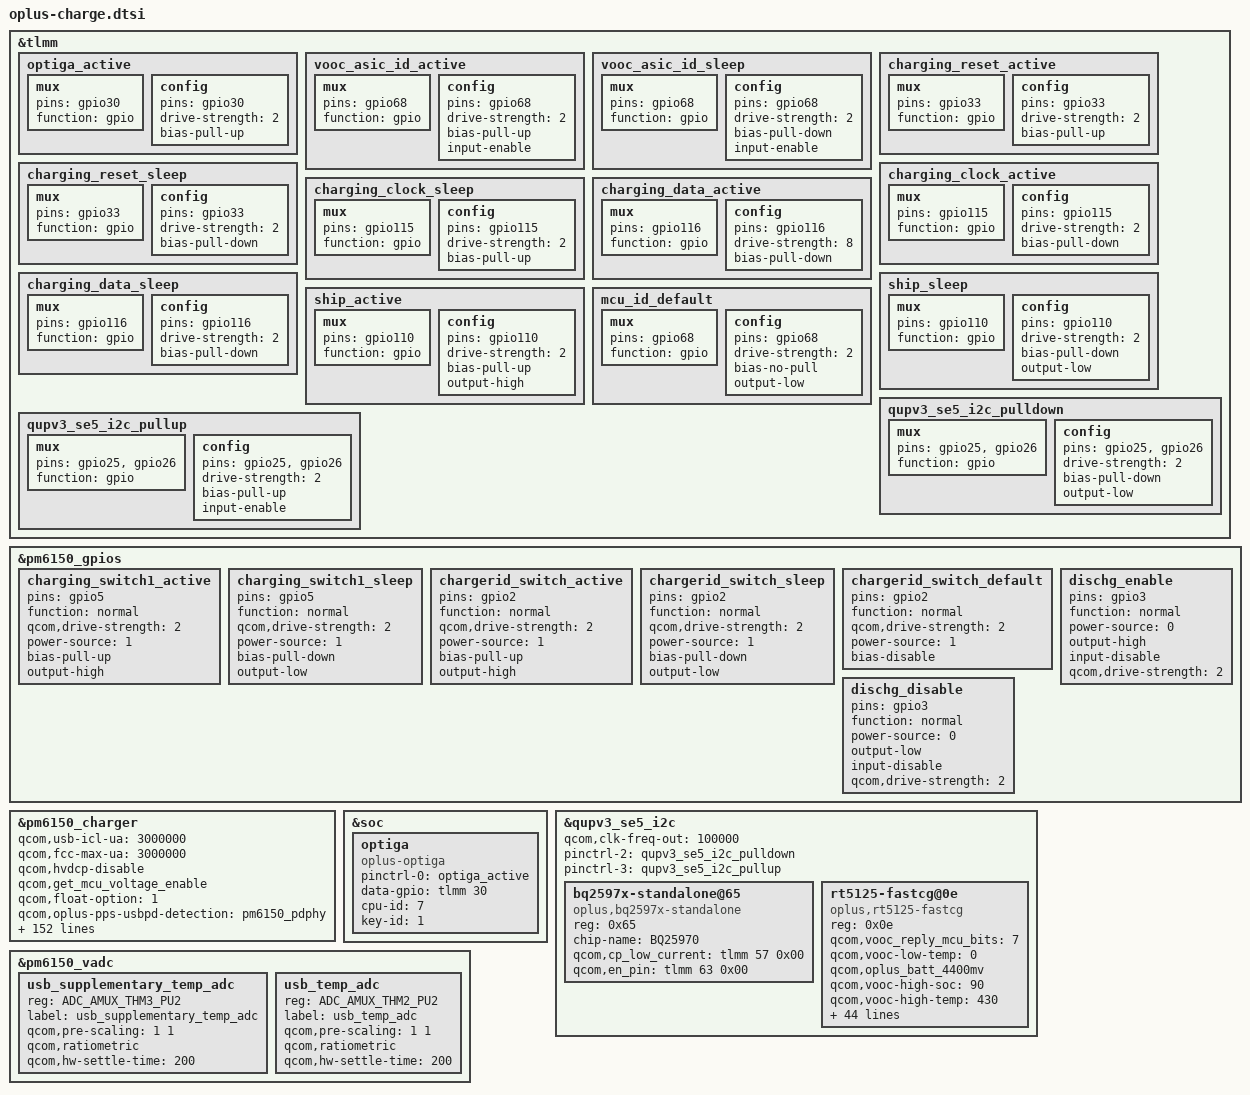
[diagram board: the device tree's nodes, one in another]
/**********************************************************************************
* Copyright (c)  2008-2019  Guangdong oplus Mobile Comm Corp., Ltd
*  
* Description: oplus Charge Module Device Tree
* 
* Version: 1.0
* Date: 2019-06-10
* Author: Gang.Yan
* 
* ------------------------------ Revision History: --------------------------------
* <version>           <date>                <author>                            <desc>
* Revision 1.0       2020-03-07            Gang.Yan             Created for new architecture
***********************************************************************************/

&tlmm {
	optiga_active: optiga_active {
				mux {
					pins = "gpio30";
					function = "gpio";
				};

				config {
					pins = "gpio30";
					drive-strength = <2>;
					bias-pull-up;
				};
	};

	vooc_asic_id_active: vooc_asic_id_active {
		mux {
			pins = "gpio68";
			function = "gpio";
		};

		config {
			pins = "gpio68";
			drive-strength = <2>;
			bias-pull-up;
			input-enable;
		};
	};

	vooc_asic_id_sleep: vooc_asic_id_sleep {
		mux {
			pins = "gpio68";
			function = "gpio";
		};

		config {
			pins = "gpio68";
			drive-strength = <2>;
			bias-pull-down;
			input-enable;
		};
	};

			charging_reset_active: charging_reset_active {
				mux {
					pins = "gpio33";
					function = "gpio";
				};

				config {
					pins = "gpio33";
					drive-strength = <2>;
					bias-pull-up;
				};
			};

			charging_reset_sleep: charging_reset_sleep {
				mux {
					pins = "gpio33";
					function = "gpio";
				};

				config {
					pins = "gpio33";
					drive-strength = <2>;
					bias-pull-down;
				};
			};

			charging_clock_active: charging_clock_active {
				mux {
					pins = "gpio115";
					function = "gpio";
				};

				config {
					pins = "gpio115";
					drive-strength = <2>;
					bias-pull-down;
				};
			};

			charging_clock_sleep: charging_clock_sleep {
				mux {
					pins = "gpio115";
					function = "gpio";
				};

				config {
					pins = "gpio115";
					drive-strength = <2>;
					bias-pull-up;
				};
			};

			charging_data_active: charging_data_active {
				mux {
					pins = "gpio116";
					function = "gpio";
				};

				config {
					pins = "gpio116";
					drive-strength = <8>;
					bias-pull-down;
				};
			};

			charging_data_sleep: charging_data_sleep {
				mux {
					pins = "gpio116";
					function = "gpio";
				};

				config {
					pins = "gpio116";
					drive-strength = <2>;
					bias-pull-down;
				};
			};


	ship_sleep: ship_sleep {
		mux {
			pins = "gpio110";
			function = "gpio";
		};

		config {
			pins = "gpio110";
			drive-strength = <2>;
			bias-pull-down;
			output-low;
		};
	};

	ship_active: ship_active {
		mux {
			pins = "gpio110";
			function = "gpio";
		};

		config {
			pins = "gpio110";
			drive-strength = <2>;
			bias-pull-up;
			output-high;
		};
	};

	
	mcu_id_default: mcu_id_default {
		mux {
					pins = "gpio68";
			function = "gpio";
		};

		config {
					pins = "gpio68";
			drive-strength = <2>;
			bias-no-pull;
			output-low;
		};
	};
			qupv3_se5_i2c_pulldown: qupv3_se5_i2c_pulldown {
				mux {
					pins = "gpio25", "gpio26";
					function = "gpio";
				};

				config {
					pins = "gpio25", "gpio26";
					drive-strength = <2>;
					bias-pull-down;
					output-low;
				};
			};

			qupv3_se5_i2c_pullup: qupv3_se5_i2c_pullup {
				mux {
					pins = "gpio25", "gpio26";
					function = "gpio";
				};

				config {
					pins = "gpio25", "gpio26";
					drive-strength = <2>;
					bias-pull-up;
					input-enable;
				};
			};
			//#endif
};

&pm6150_gpios {
	charging_switch1_active: charging_switch1_active {
		pins = "gpio5";
		function = "normal";
		qcom,drive-strength = <2>;
		power-source = <1>;
		bias-pull-up;
		output-high;
	};

	charging_switch1_sleep: charging_switch1_sleep {
		pins = "gpio5";
		function = "normal";
		qcom,drive-strength = <2>;
		power-source = <1>;
		bias-pull-down;
		output-low;
	};

	chargerid_switch_active: chargerid_switch_active {
		pins = "gpio2";
		function = "normal";
		qcom,drive-strength = <2>;
		power-source = <1>;
		bias-pull-up;
		output-high;
	};

	chargerid_switch_sleep: chargerid_switch_sleep {
		pins = "gpio2";
		function = "normal";
		qcom,drive-strength = <2>;
		power-source = <1>;
		bias-pull-down;
		output-low;
	};

	chargerid_switch_default: chargerid_switch_default {
		pins = "gpio2";
		function = "normal";
		qcom,drive-strength = <2>;
		power-source = <1>;
		bias-disable;
	};
	dischg_enable: dischg_enable {
		pins = "gpio3";
		function = "normal";
		power-source = <0>;
		output-high;
		input-disable;
		qcom,drive-strength = <2>;
	};

	dischg_disable: dischg_disable {
		pins = "gpio3";
		function = "normal";
		power-source = <0>;
		output-low;
		input-disable;
		qcom,drive-strength = <2>;
	};
};

&pm6150_charger {
			qcom,usb-icl-ua = <3000000>;
			qcom,fcc-max-ua = <3000000>;
			qcom,hvdcp-disable;
			qcom,get_mcu_voltage_enable;
			qcom,float-option = <1>;
			qcom,oplus-pps-usbpd-detection = <&pm6150_pdphy>;
			//for oplus chg framework:
			qcom,smart_charging_screenoff;
			qcom,input_current_charger_ma = <2000>;
			qcom,pd_input_current_charger_ma = <1500>;
			qcom,qc_input_current_charger_ma = <1500>;
			qcom,input_current_usb_ma = <500>;

			qcom,input_current_led_ma = <1200>;
			qcom,input_current_led_ma_high = <1200>;
			qcom,input_current_led_ma_warm = <1500>;
			qcom,input_current_led_ma_normal = <2000>;

			qcom,input_current_camera_ma = <1200>;
			qcom,input_current_cdp_ma = <1600>;
			//qcom,input_current_led_ma_overtemp = <900>;
			qcom,overtemp_bat_decidegc = <350>;
			qcom,iterm_disabled = <0>;
			sw_full_count = <25>;
			qcom,iterm_ma = <221>;
			qcom,recharge-mv = <100>;
			qcom,batt_capacity_mah = <4220>;/*typical capacity*/
			//qcom,batt_capacity_mah = <3920>; /*rated capacity*/

			qcom,removed_bat_decidegc = <190>;  /*<-19C*/

			qcom,cold_bat_decidegc = <20>;  /*-2C~0C*/
			qcom,temp_cold_vfloat_mv = <3980>;
			qcom,temp_cold_fastchg_current_ma = <314>;

			qcom,little_cold_bat_decidegc = <0>;	/*0C~5C*/
			qcom,temp_little_cold_vfloat_mv = <4435>;
			qcom,temp_little_cold_fastchg_current_ma_high = <2200>;
			qcom,temp_little_cold_fastchg_current_ma_low = <2200>;
			qcom,pd_temp_little_cold_fastchg_current_ma_high = <2594>;
			qcom,pd_temp_little_cold_fastchg_current_ma_low = <3300>;
			qcom,temp_little_cold_fastchg_current_ma = <1076>;
			qcom,qc_temp_little_cold_fastchg_current_ma_high = <2594>;
			qcom,qc_temp_little_cold_fastchg_current_ma_low = <3300>;
        
			qcom,cool_bat_decidegc = <50>;	/*5C~12C*/
			qcom,temp_cool_vfloat_mv = <4435>;
			qcom,temp_cool_fastchg_current_ma_high = <2200>;
			qcom,temp_cool_fastchg_current_ma_low = <2200>;
			qcom,qc_temp_cool_fastchg_current_ma_high = <3300>;	//2464
			qcom,qc_temp_cool_fastchg_current_ma_low = <3300>;	//1760
			qcom,pd_temp_cool_fastchg_current_ma_high = <3300>;	//2464
			qcom,pd_temp_cool_fastchg_current_ma_low = <3300>;	//1760

			qcom,little_cool_bat_decidegc = <120>;	/*12C~16C*/
			qcom,temp_little_cool_vfloat_mv = <4435>;
			qcom,temp_little_cool_fastchg_current_ma = <2200>;
			qcom,pd_temp_little_cool_fastchg_current_ma = <3300>;
			qcom,qc_temp_little_cool_fastchg_current_ma = <3300>;
	
			qcom,normal_bat_decidegc = <160>;	/*16C~44C*/
			qcom,temp_normal_fastchg_current_ma = <2200>;
			qcom,pd_temp_normal_fastchg_current_ma = <3300>;
			qcom,qc_temp_normal_fastchg_current_ma = <3300>;
			qcom,temp_normal_vfloat_mv = <4435>;

			qcom,warm_bat_decidegc = <450>;		/*44C~53C*/ /*8pin Bat Vooc project need add 3 degree C*/
			qcom,temp_warm_vfloat_mv = <4130>;
			qcom,temp_warm_fastchg_current_ma = <1152>;
			qcom,pd_temp_warm_fastchg_current_ma = <1152>;
			qcom,qc_temp_warm_fastchg_current_ma = <1152>;
			qcom,temp_warm_fastchg_current_ma_led_on = <500>;
	
			qcom,hot_bat_decidegc = <530>;

			qcom,non_standard_vfloat_mv = <3980>;
			qcom,non_standard_fastchg_current_ma = <550>;
	
			qcom,short_c_bat_cv_mv = <4330>;
			qcom,short_c_bat_vfloat_mv = <3800>;
			qcom,short_c_bat_fastchg_current_ma = <512>;

			qcom,cold_vfloat_sw_limit = <3930>;
			qcom,little_cold_vfloat_sw_limit = <4370>;
			qcom,cool_vfloat_sw_limit = <4370>;
			qcom,little_cool_vfloat_sw_limit = <4370>;
			qcom,normal_vfloat_sw_limit = <4435>;
			qcom,warm_vfloat_sw_limit = <4080>;
			qcom,non_standard_vfloat_sw_limit = <3930>;
			qcom,short_c_bat_vfloat_sw_limit = <3750>;

			qcom,max_chg_time_sec = <36000>;
			qcom,charger_hv_thr = <11000>;
			qcom,charger_recv_thr = <9700>;
			qcom,charger_lv_thr = <3400>;
			qcom,vbatt_full_thr = <4400>;
			qcom,vbatt_hv_thr = <4600>;
			qcom,vfloat_step_mv = <16>;
			qcom,non_standard_vfloat_over_sw_limit = <3980>;
			qcom,cold_vfloat_over_sw_limit = <3980>;
			qcom,little_cold_vfloat_over_sw_limit = <4440>;
			qcom,cool_vfloat_over_sw_limit = <4440>;
			qcom,little_cool_vfloat_over_sw_limit = <4440>;
			qcom,normal_vfloat_over_sw_limit = <4440>;
			qcom,warm_vfloat_over_sw_limit = <4130>;

			qcom,vbatt_power_off = <3300>;
			qcom,vbatt_soc_1 = <3410>;
			qcom,vooc_project = <3>;
			qcom,vbatt_num = <1>;
			qcom,ffc_support;

			qcom,normal_vterm_hw_inc = <18>;
			qcom,non_normal_vterm_hw_inc = <18>;

			qcom,ff1_normal_fastchg_ma = <1550>;
			qcom,ff1_warm_fastchg_ma = <1750>;	/* 35C ~ 40c */
			qcom,ff1_exit_step_ma = <100>;
			qcom,ff1_warm_exit_step_ma = <150>;
			qcom,ffc2_normal_fastchg_ma = <1550>;/*12C~35c*/
			qcom,ffc2_warm_fastchg_ma = <1750>;	/* 35C ~ 40c */
			qcom,ffc2_temp_warm_decidegc = <350>;
			qcom,ffc2_temp_high_decidegc = <450>;
			qcom,ffc2_temp_low_decidegc = <160>;
			qcom,ffc2_exit_step_ma = <100>;
			qcom,ffc2_warm_exit_step_ma = <150>;
			
			qcom,ffc_normal_vfloat_sw_limit = <4485>;
			qcom,ffc2_normal_vfloat_sw_limit = <4485>;
			qcom,ffc_temp_normal_vfloat_mv = <4550>;
			qcom,ffc_normal_vfloat_over_sw_limit = <4550>;

			qcom,default_iterm_ma = <221>;
			qcom,default_temp_normal_fastchg_current_ma = <2200>;
			qcom,default_normal_vfloat_sw_limit = <4385>;
			qcom,default_temp_normal_vfloat_mv = <4435>;
			qcom,default_normal_vfloat_over_sw_limit = <4440>;

			qcom,default_temp_little_cool_fastchg_current_ma = <2200>;
			qcom,default_little_cool_vfloat_sw_limit = <4385>;
			qcom,default_temp_little_cool_vfloat_mv = <4435>;
			qcom,default_little_cool_vfloat_over_sw_limit = <4445>;
			qcom,vbatt_pdqc_to_5v_thr = <4500>;
			qcom,vbatt_pdqc_to_9v_thr = <4500>;
			qcom,smart_charge_version = <1>;

			qcom,vooc_show_ui_soc_decimal;
			qcom,usbtemp_batttemp_high_gap = <14>;
			qcom,ui_soc_decimal_speedmin = <20>;//2A

			///qcom,offset_temp = <30>;
			//for control:
			//qcom,suspend_after_full;
			qcom,check_batt_full_by_sw;
			//qcom,external_gauge;
                        qcom,external_authenticate;
			qcom,fg_bcl_poll_enable;
			qcom,chg_ctrl_by_lcd;
			qcom,chg_ctrl_by_camera;
			qcom,sw_vfloat_over_protect_enable;
			qcom,lpd-disable;
			//qcom,smooth_switch;
			qcom,dual_ffc;

			qcom,chargerid_switch-gpio = <&pm6150_gpios 2 0x00>;
			qcom,ship-mode-config = <1>;
			qcom,ship-gpio = <&tlmm 110 0x00>;
			//qcom,shortc-gpio = <&tlmm 43 0x00>;
			qcom,dischg-gpio = <&pm6150_gpios 3 0x00>;

			pinctrl-names =
							"chargerid_switch_active", "chargerid_switch_sleep","chargerid_switch_default",
							"ship_active", "ship_sleep",
							"dischg_enable", "dischg_disable","mcu_id_default";

			pinctrl-0 = <&chargerid_switch_active>;
			pinctrl-1 = <&chargerid_switch_sleep>;
			pinctrl-2 = <&chargerid_switch_default>;
			pinctrl-3 = <&ship_active>;
			pinctrl-4 = <&ship_sleep>;
			pinctrl-5 = <&dischg_enable>;
			pinctrl-6 = <&dischg_disable>;
			pinctrl-7 = <&mcu_id_default>;
};
&soc {
	optiga {
		compatible = "oplus-optiga";
		status = "ok";
		pinctrl-names = "optiga_active";
		pinctrl-0 = <&optiga_active>;
		data-gpio = <&tlmm 30 0x00>;
		cpu-id = <7>;
		key-id = <1>;
	};
};

&qupv3_se5_i2c {
	status = "ok";
	qcom,clk-freq-out = <100000>;
	pinctrl-names = "default", "sleep", "pulldown", "pullup";
	pinctrl-2 = <&qupv3_se5_i2c_pulldown>;
	pinctrl-3 = <&qupv3_se5_i2c_pullup>;
//#endif // 
/*
	oplus_short-ic@58 {
			status = "okay";
			compatible = "oplus,oplus_short-ic";
			reg = <0x58>;
			qcom,modify-soc-smooth;
		};
		*/
	bq2597x-standalone@65 {
		status = "okay";
		compatible = "oplus,bq2597x-standalone";
		reg = <0x65>;
		chip-name = "BQ25970";
		qcom,cp_low_current = <&tlmm 57 0x00>;
		qcom,en_pin = <&tlmm 63 0x00>;
	};
	
	rt5125-fastcg@0e{
		status = "okay";
		compatible = "oplus,rt5125-fastcg";
		reg = <0x0e>;
		qcom,vooc_reply_mcu_bits = <7>;
		qcom,vooc-low-temp = <0>;
		qcom,oplus_batt_4400mv;
		qcom,vooc-high-soc = <90>;
		qcom,vooc-high-temp = <430>;
		qcom,vooc_batt_over_high_temp = <440>;
		//qcom,vooc_fw_update_newmethod;
		qcom,vooc-fw-type = <2>;
		qcom,support-single-batt-svooc;
		qcom,vooc_multistep_adjust_current_support;
		qcom,vooc_multistep_initial_batt_temp = <1000>;
		qcom,vooc_strategy_normal_current = <0x09>;

		qcom,vooc_strategy1_batt_high_temp0 = <385>;
		qcom,vooc_strategy1_batt_high_temp1 = <395>;
		qcom,vooc_strategy1_batt_high_temp2 = <420>;
		qcom,vooc_strategy1_batt_low_temp2 = <410>;
		qcom,vooc_strategy1_batt_low_temp1 = <385>;
		qcom,vooc_strategy1_batt_low_temp0 = <375>;

		qcom,vooc_strategy1_high_current0 = <0x07>;
		qcom,vooc_strategy1_high_current1 = <0x05>;
		qcom,vooc_strategy1_high_current2 = <0x03>;
		qcom,vooc_strategy1_low_current2 = <0x05>;
		qcom,vooc_strategy1_low_current1 = <0x07>;
		qcom,vooc_strategy1_low_current0 = <0x09>;
/*
		qcom,vooc_strategy1_batt_high_temp0 = <710>;
		qcom,vooc_strategy1_batt_high_temp1 = <720>;
		qcom,vooc_strategy1_batt_high_temp2 = <735>;
		qcom,vooc_strategy1_batt_low_temp2 = <715>;
		qcom,vooc_strategy1_batt_low_temp1 = <700>;
		qcom,vooc_strategy1_batt_low_temp0 = <690>;

		qcom,vooc_strategy1_high_current0 = <0x03>;
		qcom,vooc_strategy1_high_current1 = <0x02>;
		qcom,vooc_strategy1_high_current2 = <0x02>;
		qcom,vooc_strategy1_low_current2 = <0x02>;
		qcom,vooc_strategy1_low_current1 = <0x02>;
		qcom,vooc_strategy1_low_current0 = <0x03>;
*/
		qcom,vooc_current_lvl = <2000
									3000
									4000
									5000
									6000
									7000
									8000
									9000
									10000>;

		pinctrl-names = "switch1_act_switch2_act", "switch1_sleep_switch2_sleep",
						"switch1_act_switch3_act", "switch1_sleep_switch3_sleep",
						"switch1_act_switch2_sleep", "switch1_sleep_switch2_act",
						"clock_active","clock_sleep",
						"data_active","data_sleep",
						"reset_active","reset_sleep",
						"vooc_asic_id_active","vooc_asic_id_sleep";
		pinctrl-0 = <&charging_switch1_active>;
		pinctrl-1 = <&charging_switch1_sleep>;
		pinctrl-2 = <&charging_switch1_active>;
		pinctrl-3 = <&charging_switch1_sleep>;
		pinctrl-4 = <&charging_switch1_active>;
		pinctrl-5 = <&charging_switch1_sleep>;
		pinctrl-6 = <&charging_clock_active>;
		pinctrl-7 = <&charging_clock_sleep>;
		pinctrl-8 = <&charging_data_active>;
		pinctrl-9 = <&charging_data_sleep>;
		pinctrl-10 = <&charging_reset_active>;
		pinctrl-11 = <&charging_reset_sleep>;
		pinctrl-12 = <&vooc_asic_id_active>;
		pinctrl-13 = <&vooc_asic_id_sleep>;
		
		qcom,charging_switch1-gpio 		= <&pm6150_gpios 5 0x00>;
		qcom,charging_switch1_ctr1-gpio 	= <&pm6150_gpios 6 0x00>;

		qcom,charging_reset-gpio = <&tlmm 33 0x00>;
		qcom,charging_clock-gpio = <&tlmm 115 0x00>;
		qcom,charging_data-gpio = <&tlmm 116 0x00>;
		qcom,vooc_asic_id-gpio = <&tlmm 68 0x00>;

		qcom,parse_fw_from_dt;
		vooc,firmware_data = [
			90 06 00 20 a1 00 00 00 a9 00 00 00 ab 00 00 00 00 00 00 00 00 00 00 00 00 00 00 00 00 00 00 00 
			00 00 00 00 00 00 00 00 00 00 00 00 ad 00 00 00 00 00 00 00 00 00 00 00 af 00 00 00 b1 00 00 00 
			65 09 00 00 95 0e 00 00 f5 0c 00 00 b3 00 00 00 79 0e 00 00 d1 08 00 00 75 0d 00 00 89 0d 00 00 
			69 0e 00 00 09 0d 00 00 19 0d 00 00 51 08 00 00 e1 0b 00 00 f1 0b 00 00 01 0c 00 00 b3 00 00 00 
			1d 0c 00 00 b3 00 00 00 29 0d 00 00 03 48 85 46 00 f0 a0 fb 00 48 00 47 95 27 00 00 90 06 00 20 
			04 48 80 47 04 48 00 47 fe e7 fe e7 fe e7 fe e7 fe e7 fe e7 71 0d 00 00 8d 00 00 00 70 b5 00 24 
			25 46 00 28 01 da 01 24 40 42 00 29 01 da 01 25 49 42 00 f0 95 fa ac 42 00 d0 40 42 00 2c 00 d0 
			49 42 70 bd f8 b5 02 46 4a 40 d4 0f 42 00 4b 00 52 08 5b 08 9a 42 02 d2 02 46 08 46 11 46 4a 00 
			23 d0 c3 0d 4a 00 dd b2 12 0e ad 1a 20 2d 35 da 49 02 01 26 49 0a f6 05 8a 19 00 2c 00 d0 52 42 
			20 21 4f 1b 11 46 b9 40 2a 41 10 18 c2 0d 9a 42 21 d0 00 2c 17 d0 01 2d 08 dc da 05 80 1a d2 0f 
			80 19 d2 07 db b2 00 f0 ad fa f8 bd da 05 80 1a 01 23 40 00 1b 06 c0 18 80 18 5a 42 80 18 ca 0f 
			10 43 49 00 07 e0 49 08 c2 07 11 43 da 05 80 1a 80 19 40 08 80 18 00 f0 8d fa f8 bd 61 00 01 22 
			51 1a 00 1b f7 e7 01 22 d2 07 51 40 aa e7 01 22 d2 07 50 40 a6 e7 02 46 70 b5 4a 40 d3 0f db 07 
			40 00 2d d0 4a 00 2a d0 01 0e 14 0e 00 02 12 02 09 19 40 0a 52 0a 84 18 e5 01 04 46 54 43 00 0a 
			12 0a 2e 04 50 43 a4 19 42 19 20 0c c5 43 aa 18 12 0c 01 25 ad 03 52 1c 52 19 12 04 7f 39 24 04 
			00 d0 52 1c 10 43 01 d4 40 00 49 1e c2 b2 0c 06 c0 09 20 18 40 1c 40 08 80 2a 02 d0 03 e0 00 20 
			70 bd 40 08 40 00 00 29 00 da 00 20 18 43 70 bd 70 b5 02 46 4a 40 d5 0f 40 00 4a 00 ed 07 40 08 
			52 08 00 28 14 d0 00 2a 12 d0 c4 0d d3 0d 41 02 01 20 c0 05 52 02 49 0a 52 0a e4 1a 09 18 12 18 
			7d 34 91 42 01 d3 64 1c 00 e0 49 00 00 2c 01 da 00 20 70 bd 00 23 91 42 01 d3 89 1a 03 43 40 08 
			49 00 00 28 f7 d1 00 29 0a d0 91 42 02 d1 01 21 c9 07 05 e0 91 42 01 d2 01 21 01 e0 01 21 c9 43 
			e0 05 c0 18 40 19 00 f0 05 fa 70 bd 42 00 05 d0 42 00 12 0e 52 42 8a 42 01 db 00 20 70 47 c9 05 
			08 18 70 47 f0 b5 07 46 08 46 58 40 87 b0 c0 0f 04 90 48 00 0e 46 59 00 40 08 49 08 bc 1a 88 41 
			05 d2 38 46 31 46 1e 46 17 46 0b 46 02 46 58 00 40 08 10 43 4c d0 30 0d 03 90 40 05 59 00 40 0d 
			49 0d 05 90 40 1a 02 90 40 28 72 da 18 03 01 21 00 0b 09 05 08 43 01 90 04 98 00 92 00 28 05 d0 
			01 99 52 42 00 20 88 41 00 92 01 90 02 98 40 21 0a 1a 01 99 00 98 00 f0 89 f9 05 46 0c 46 6b 46 
			07 cb 00 f0 a4 f9 c0 19 71 41 03 9a 0e 0d 00 23 d7 17 56 40 1a 46 7a 40 16 43 44 d0 04 9a 00 2a 
			2d d0 02 9a 01 2a 03 9a 15 dc 12 05 c0 1a 91 41 01 26 36 05 00 1c 71 41 d2 0f 05 9e d2 07 00 93 
			01 92 02 96 2a 46 23 46 00 f0 e2 f9 07 b0 f0 bd 38 46 31 46 fa e7 16 05 22 4a 0f 46 b2 18 c0 1a 
			b7 41 01 21 09 05 00 1c 4f 41 00 18 7f 41 11 46 18 18 79 41 e2 0f 10 43 6d 19 64 41 13 e0 e2 07 
			6d 08 15 43 64 08 c2 07 14 43 03 9a 01 26 12 05 c0 1a 91 41 36 05 00 1c 71 41 ce 07 40 08 30 43 
			49 08 c0 18 51 41 2a 46 23 46 00 f0 a4 f9 cd e7 ff e7 04 98 01 22 40 00 c1 17 12 1a 00 23 8b 41 
			04 98 31 46 c4 17 38 1a a1 41 ee e7 30 b4 01 24 e4 07 63 40 30 bc 55 e7 30 b4 01 24 e4 07 61 40 
			30 bc 4f e7 00 00 e0 ff f0 b5 1f b4 88 b0 0b 99 09 98 00 24 48 40 09 99 c0 0f 49 00 49 08 09 91 
			c0 07 0b 99 00 90 49 00 49 08 0b 91 09 99 08 98 a6 46 08 43 1c d0 0b 99 0a 98 08 43 18 d0 09 98 
			01 24 40 00 42 0d 48 00 41 0d 09 98 24 05 00 03 00 0b 20 43 09 90 0b 98 00 03 00 0b 20 43 0b 90 
			50 18 1c 49 40 18 00 22 01 90 14 46 10 46 05 e0 00 20 01 46 0d b0 f0 bd 03 28 01 da 03 46 00 e0 
			03 23 9c 46 c1 1a 0a ae 0a e0 5f 00 08 ad ed 5b 4f 00 f7 5b 7d 43 00 27 aa 18 7c 41 49 1c 5b 1e 
			61 45 f2 dd 41 00 04 ab 5a 52 21 04 12 0c 0a 43 24 0c 40 1c 08 28 df db 01 98 02 90 00 99 70 46 
			01 91 00 90 05 9b 04 9a 07 99 06 98 00 f0 30 f9 d0 e7 00 00 0d fc ff ff c2 17 c1 0f 50 40 10 b5 
			40 18 ca 07 96 23 00 21 00 f0 dc f8 10 bd 00 00 0e b5 c2 17 c1 0f 50 40 ca 07 40 18 00 21 05 4b 
			02 93 01 92 00 91 0a 46 0b 46 00 f0 11 f9 03 b0 00 bd 00 00 33 04 00 00 0e b5 05 49 02 91 00 21 
			00 91 0a 46 0b 46 01 91 00 f0 02 f9 03 b0 00 bd 33 04 00 00 c2 0f 41 00 40 02 01 23 40 0a db 05 
			d2 07 09 0e c0 18 7f 29 01 da 00 20 70 47 96 29 03 dc 96 23 59 1a c8 40 01 e0 96 39 88 40 00 2a 
			f4 d0 40 42 70 47 00 00 70 b5 cd 0f 4a 00 09 03 01 23 09 0b 1b 05 19 43 0b 4b ed 07 00 24 52 0d 
			9a 42 01 da 00 20 70 bd 07 4b 34 33 9a 42 03 dc 9a 1a 00 f0 5b f8 02 e0 04 49 51 18 88 40 2c 43 
			f1 d0 40 42 70 bd 00 00 ff 03 00 00 cd fb ff ff c2 0f d2 07 40 00 40 08 0b d0 c1 0d 07 23 db 01 
			c9 18 40 02 09 05 40 0a 11 43 c2 08 40 07 11 43 70 47 00 20 01 46 70 47 10 b5 00 29 04 db 01 24 
			e4 07 40 42 8c 41 21 46 00 2b 04 db 1c 46 01 23 db 07 52 42 a3 41 8b 42 00 d1 82 42 10 bd 00 00 
			30 b5 0b 46 01 46 00 20 20 22 01 24 09 e0 0d 46 d5 40 9d 42 05 d3 1d 46 95 40 49 1b 25 46 95 40 
			40 19 15 46 52 1e 00 2d f1 dc 30 bd 10 b5 20 2a 04 db 01 46 20 3a 91 40 00 20 10 bd 91 40 20 23 
			9c 1a 03 46 e3 40 19 43 90 40 10 bd 10 b5 20 2a 04 db 08 46 20 3a d0 40 00 21 10 bd 0b 46 d3 40 
			d0 40 20 24 a2 1a 91 40 08 43 19 46 10 bd 10 b5 20 2a 06 db cb 17 08 46 20 3a 10 41 c1 17 0b 43 
			06 e0 0b 46 13 41 d0 40 20 24 a2 1a 91 40 08 43 19 46 10 bd 00 29 04 da 40 1c 49 00 01 d1 40 08 
			40 00 70 47 70 b4 00 24 05 0c 05 d1 10 24 00 04 02 d1 00 29 21 d0 11 24 05 0e 01 d1 00 02 08 34 
			05 0f 01 d1 00 01 24 1d 85 0f 01 d1 80 00 a4 1c 00 28 01 db 40 00 64 1c 00 29 08 d0 20 25 2e 1b 
			0d 46 f5 40 a1 40 00 d0 01 21 29 43 08 43 01 06 1b 1b 00 0a db 1d 02 d5 00 20 70 bc 70 47 db 05 
			18 18 80 18 00 29 f8 da 40 1c 49 00 f5 d1 70 bc 40 08 40 00 70 47 10 b5 00 2b 08 da 00 24 40 1c 
			61 41 92 18 5b 41 1a 43 01 d1 40 08 40 00 10 bd f0 b5 1f b4 82 b0 05 46 0c 00 03 d0 08 46 00 f0 
			b3 fb 02 e0 00 f0 b0 fb 20 30 02 46 00 90 21 46 28 46 ff f7 6b ff 04 9b 05 9a 04 46 0f 46 18 43 
			11 43 08 43 14 d0 18 46 10 43 1b d0 00 98 40 21 0a 1a 18 46 05 99 ff f7 69 ff 05 46 0e 46 00 9a 
			05 99 04 98 ff f7 52 ff 08 43 05 d0 01 20 04 e0 20 46 39 46 07 b0 f0 bd 00 20 c1 17 05 43 0e 43 
			2c 43 37 43 00 99 0e 98 63 05 40 1a 79 05 e4 0a 00 22 0c 43 fd 0a 0a 30 02 d5 00 20 01 46 e9 e7 
			01 05 10 19 69 41 0c 9c 0d 9d 00 19 69 41 ff f7 a2 ff df e7 06 4c 01 25 06 4e 05 e0 e3 68 07 cc 
			2b 43 0c 3c 98 47 10 34 b4 42 f7 d3 ff f7 52 fc c4 30 00 00 e4 30 00 00 70 b5 8c 18 05 78 40 1c 
			6b 07 5b 0f 01 d1 03 78 40 1c 2a 11 06 d1 02 78 40 1c 03 e0 06 78 0e 70 40 1c 49 1c 5b 1e f9 d1 
			2b 07 05 d4 00 23 52 1e 0d d4 0b 70 49 1c fa e7 03 78 40 1c cb 1a 92 1c 03 e0 1d 78 0d 70 49 1c 
			5b 1c 52 1e f9 d5 a1 42 d8 d3 00 20 70 bd 00 00 02 48 01 68 82 14 91 43 01 60 70 47 00 70 00 40 
			10 b5 0c 4c 01 20 e0 62 06 20 00 f0 e1 f8 00 20 00 f0 62 fa 60 68 01 28 0a d0 01 21 06 20 00 f0 
			d7 f8 00 20 a0 62 06 20 00 f0 d2 f8 08 46 10 bd 00 21 f3 e7 00 03 0a 42 00 b5 00 23 0b 49 01 22 
			00 28 01 d0 cb 62 00 e0 ca 62 8a 62 06 20 00 f0 bf f8 06 20 00 f0 bc f8 06 20 00 f0 b9 f8 8b 62 
			06 20 00 f0 b5 f8 ca 62 00 bd 00 00 00 03 0a 42 05 48 c0 69 05 49 c8 70 05 48 01 68 01 22 92 04 
			91 43 01 60 70 47 00 00 00 30 00 40 89 02 00 20 00 70 00 40 f0 b5 07 46 0e 46 14 46 00 25 00 f0 
			29 f9 ca 20 00 f0 4e f9 01 28 07 d0 6d 1c ed b2 01 20 00 f0 19 f9 0a 2d f1 d9 f0 bd 38 46 00 f0 
			41 f9 01 28 03 d0 01 20 00 f0 0e f9 f0 bd 00 f0 11 f9 cb 20 00 f0 36 f9 01 28 0a d0 01 20 00 f0 
			03 f9 f0 bd 01 20 00 f0 d3 f8 20 70 64 1c 76 1e f6 b2 01 2e f6 d8 00 20 00 f0 ca f8 20 70 00 f0 
			0d f9 f0 bd 70 b5 2e 48 01 68 01 22 d2 05 91 43 01 60 2c 4b 98 69 c0 b2 14 21 06 46 2a 4a 0e 40 
			d1 1c 02 25 29 4c 00 2e 0f d0 10 78 56 78 80 19 40 5c 99 68 09 0a 09 02 01 43 99 60 50 78 40 1c 
			50 70 20 68 28 43 20 60 70 bd 06 07 12 d5 20 68 c0 07 08 d0 d8 68 13 78 94 78 1b 19 58 54 90 78 
			40 1c 90 70 70 bd d8 68 10 70 20 68 01 21 08 43 20 60 70 bd c6 07 13 d0 20 68 80 07 f9 d4 10 78 
			00 28 f6 d1 90 78 02 28 f3 d3 10 78 40 5c 12 78 0d 49 09 1d 51 5c 09 02 08 43 00 f0 4d f8 70 bd 
			80 07 0b d5 00 20 10 70 90 70 50 70 20 68 40 08 40 00 20 60 20 68 a8 43 20 60 70 bd d8 68 70 bd 
			00 70 00 40 00 30 00 40 89 01 00 20 74 01 00 20 00 e0 40 1e 00 28 fc d1 70 47 f0 b5 07 46 0d 46 
			16 46 00 24 00 f0 86 f8 ca 20 00 f0 ab f8 01 28 07 d0 64 1c e4 b2 01 20 00 f0 76 f8 0a 2c f1 d9 
			f0 bd 38 46 00 f0 9e f8 01 28 0f d0 01 20 00 f0 6b f8 f0 bd 30 78 76 1c 00 f0 94 f8 01 28 03 d0 
			01 20 00 f0 61 f8 f0 bd 6d 1e ed b2 00 2d f1 d1 00 f0 74 f8 f0 bd 00 00 10 b5 04 24 11 4a 08 23 
			11 49 03 28 0b d0 04 28 10 d0 10 49 05 28 14 d0 06 28 03 d1 08 78 40 08 40 00 08 70 10 bd 10 68 
			18 43 10 60 08 69 20 43 08 61 10 bd 10 68 98 43 10 60 08 69 a0 43 08 61 10 bd 08 78 01 22 10 43 
			08 70 10 bd 74 01 00 20 00 ed 00 e0 71 01 00 20 7c b5 06 46 00 25 01 95 08 20 00 90 11 4c 16 e0 
			6a 46 10 79 40 00 01 90 00 20 00 f0 15 f9 06 20 ff f7 8e ff 61 68 6a 46 10 79 01 43 01 91 a5 62 
			04 20 ff f7 85 ff 6a 46 10 78 40 1e 00 90 68 46 00 78 00 28 e4 d1 30 46 ff f7 ae fe 68 46 00 79 
			7c bd 00 00 00 03 0a 42 00 b5 00 28 01 d0 00 f0 15 f8 00 bd 00 b5 01 20 00 f0 ee f8 00 20 00 f0 
			eb f8 0c 20 ff f7 64 ff 03 49 00 22 ca 62 0c 20 ff f7 5e ff 8a 62 00 bd 00 03 0a 42 00 b5 08 48 
			00 21 81 62 c1 62 06 20 ff f7 52 ff 00 20 00 f0 d3 f8 06 20 ff f7 4c ff 01 20 00 f0 cd f8 00 bd 
			00 03 0a 42 f0 b5 05 46 08 24 0c 4e 00 27 e8 09 f0 62 06 20 ff f7 3c ff 00 20 00 f0 bd f8 06 20 
			ff f7 36 ff 00 bf 68 06 05 0e b7 62 64 1e e4 b2 00 2c ec d1 b7 62 ff f7 43 fe f0 bd 00 03 0a 42 
			02 48 01 68 c2 14 91 43 01 60 70 47 00 70 00 40 02 48 01 68 02 15 91 43 01 60 70 47 00 70 00 40 
			04 48 01 68 42 15 91 43 01 60 03 49 01 20 08 70 70 47 00 00 00 70 00 40 0a 00 00 20 10 b5 0e 49 
			08 68 80 22 90 43 08 60 0c 49 08 68 00 28 08 d1 0b 4a 13 68 01 20 03 43 13 60 0a 4b 00 22 1a 70 
			08 60 09 48 00 78 02 28 02 d0 00 f0 49 fb 10 bd 00 f0 5e f9 10 bd 00 00 00 70 00 40 6c 01 00 20 
			00 10 00 40 27 00 00 20 30 00 00 20 83 07 ff 22 db 0e 9a 40 89 07 09 0e 99 40 00 28 0b da 00 07 
			00 0f 08 38 83 08 08 48 9b 00 18 18 c3 69 93 43 0b 43 c3 61 70 47 83 08 04 48 9b 00 18 18 03 68 
			93 43 0b 43 03 60 70 47 00 ed 00 e0 00 e4 00 e0 83 07 ff 22 db 0e 9a 40 89 07 09 0e 99 40 00 28 
			0b da 00 07 00 0f 08 38 83 08 08 48 9b 00 18 18 c3 69 93 43 0b 43 c3 61 70 47 83 08 04 48 9b 00 
			18 18 03 68 93 43 0b 43 03 60 70 47 00 ed 00 e0 00 e4 00 e0 03 48 01 68 01 22 52 05 91 43 01 60 
			70 47 00 00 00 70 00 40 02 48 01 68 02 14 91 43 01 60 70 47 00 70 00 40 02 48 01 68 42 14 91 43 
			01 60 70 47 00 70 00 40 02 48 01 68 20 22 91 43 01 60 70 47 00 70 00 40 10 b5 00 21 01 24 0a 4b 
			0a 4a 00 28 04 d0 0b e0 94 62 49 1c 99 42 02 d8 10 68 00 28 f8 d0 10 bd d4 62 49 1c 99 42 fa d8 
			50 68 00 28 f8 d0 10 bd 50 c3 00 00 00 03 0a 42 70 47 00 00 03 48 01 68 01 22 52 04 91 43 01 60 
			70 47 00 00 00 70 00 40 70 b5 2a 48 01 68 01 22 12 04 91 43 01 60 28 49 08 88 00 28 02 d0 40 1e 
			08 80 0e e0 7d 20 c0 00 08 80 24 49 08 88 00 28 01 d0 40 1e 08 80 22 49 08 88 00 28 01 d0 40 1e 
			08 80 20 49 08 68 00 28 01 d0 40 1e 08 60 1e 49 08 68 00 28 01 d0 40 1e 08 60 1c 49 08 68 00 28 
			01 d0 40 1e 08 60 1a 49 08 78 00 28 01 d0 40 1e 08 70 18 49 08 68 00 28 01 d0 40 1e 08 60 16 49 
			08 68 00 28 01 d0 40 1e 08 60 14 49 08 78 40 1c c0 b2 08 70 c8 28 0c d9 00 20 08 70 10 4c 01 25 
			20 78 00 28 04 d0 00 20 01 f0 40 fc 0d 48 05 70 25 70 70 bd 00 70 00 40 68 01 00 20 3a 00 00 20 
			3c 00 00 20 6c 00 00 20 70 00 00 20 74 00 00 20 28 00 00 20 78 00 00 20 7c 00 00 20 27 00 00 20 
			12 00 00 20 09 00 00 20 02 48 01 68 c2 13 91 43 01 60 70 47 00 70 00 40 04 49 0f 20 c8 60 04 48 
			01 68 01 22 d2 04 91 43 01 60 70 47 00 60 00 40 00 70 00 40 03 48 01 68 01 22 92 05 91 43 01 60 
			70 47 00 00 00 70 00 40 20 21 02 0c 01 d0 10 21 10 46 02 0a 01 d0 10 46 08 39 02 09 01 d0 10 46 
			09 1f 82 08 01 d0 10 46 89 1e 42 08 01 d0 88 1e 70 47 08 1a 70 47 30 b4 74 46 64 1e 25 78 64 1c 
			ab 42 00 d2 1d 46 63 5d 5b 00 e3 18 30 bc 18 47 02 e0 08 c8 12 1f 08 c1 00 2a fa d1 70 47 70 47 
			00 20 01 e0 01 c1 12 1f 00 2a fb d1 70 47 00 00 f8 b5 f0 4f f8 7b 08 28 08 d2 01 f0 e7 fb 3a 46 
			f9 7b 80 32 50 54 49 1c f9 73 f8 bd e9 4c 01 26 e9 4d 20 34 08 28 66 d1 09 20 f8 73 01 f0 a6 fe 
			20 46 60 30 01 78 01 29 05 d1 42 78 00 2a 02 d1 82 78 01 2a 03 d0 02 23 01 29 15 d0 1a e0 c2 78 
			81 79 d2 00 11 43 02 79 40 79 92 00 40 00 02 43 11 43 79 74 60 7c 00 28 45 d1 28 70 6e 70 ae 70 
			03 20 60 74 26 74 3e e0 41 78 00 29 02 d1 81 78 00 29 03 d0 41 78 01 29 0f d0 14 e0 c2 78 81 79 
			d2 00 11 43 02 79 40 79 92 00 40 00 02 43 11 43 79 74 00 20 60 74 23 74 25 e0 82 78 00 2a 02 d1 
			c2 78 01 2a 02 d0 01 29 15 d0 1a e0 02 79 c1 79 d2 00 11 43 42 79 80 79 92 00 40 00 02 43 11 43 
			79 74 60 7c 00 28 a0 d1 28 70 6e 70 ae 70 03 20 60 74 26 74 f8 bd 81 78 00 29 02 d1 c1 78 00 29 
			05 d0 01 f0 c7 fe 38 7c 00 28 0f d0 25 e1 02 79 c1 79 d2 00 11 43 42 79 80 79 92 00 40 00 02 43 
			11 43 79 74 00 20 60 74 23 74 f8 bd 00 21 e9 70 29 71 69 71 a9 71 e9 71 29 72 69 72 78 7e 02 28 
			24 d0 01 28 27 d0 38 7f 05 28 2a d0 04 28 37 d0 03 28 3a d0 02 28 3f d0 01 28 44 d0 78 7f 00 28 
			4e d0 40 1e c1 00 9b 4a 08 1a 88 32 11 5c e9 70 80 18 41 78 29 71 81 78 69 71 c1 78 a9 71 01 79 
			e9 71 41 79 29 72 80 79 68 72 e6 e0 78 7c 00 01 b8 76 6e 71 e1 e0 b8 7e 79 7c 08 43 b8 76 6e 71 
			db e0 a8 7a e8 70 e8 7a 28 71 28 7b 68 71 68 7b a8 71 a8 7b e8 71 e8 7b 28 72 28 7c 68 72 cc e0 
			78 7c 00 03 f8 86 6e 71 c7 e0 78 7c f9 8e 00 02 08 43 f8 86 6e 71 c0 e0 78 7c f9 8e 00 01 08 43 
			f8 86 6e 71 b9 e0 f8 8e 79 7c 08 43 f8 86 00 f0 67 fc 6e 71 38 8f f9 8e 88 42 00 d1 fe 77 ac e0 
			78 7c 09 28 0c d0 79 76 39 77 03 00 ff f7 e3 fe 0e 0f 12 50 60 7e 8a a5 a5 a5 a5 a5 a5 8f 9f a5 
			79 76 39 77 00 20 01 f0 c1 fa be 73 f8 bd 01 f0 31 fe f8 bd a0 79 00 28 0b d0 e0 7b 00 28 03 d0 
			ae 71 c0 43 e0 73 88 e0 ee 70 2e 71 2e 72 6e 72 f7 e7 60 7a 00 28 09 d0 ee 70 2e 71 6e 71 ae 71 
			ee 71 2e 72 6e 72 40 1e 60 72 76 e0 5b 49 78 6e 88 42 01 da 00 20 05 e0 58 4a 0a 21 52 42 80 18 
			fe f7 9c ff 41 06 c9 0f e9 70 81 06 c9 0f 29 71 c1 06 c9 0f 69 71 01 07 c9 0f a9 71 41 07 c9 0f 
			e9 71 81 07 c9 0f 29 72 c0 07 c0 0f 68 72 54 e0 09 21 08 20 01 f0 54 ff 38 71 02 28 03 d0 01 28 
			03 d0 6e 71 49 e0 2e 71 47 e0 2e 71 6e 71 44 e0 a0 7a 40 06 c0 0f e8 70 a0 7a 80 06 c0 0f 28 71 
			a0 7a c0 06 c0 0f 68 71 a0 7a 00 07 c0 0f a8 71 a0 7a 40 07 c0 0f e8 71 a0 7a 80 07 c0 0f 28 72 
			a0 7a c0 07 c0 0f 68 72 61 72 26 e0 3e 70 60 7c 00 28 02 d0 79 73 40 1e 60 74 78 7b e8 70 2e 71 
			6e 71 1a e0 03 20 78 76 2e 71 ae 71 15 e0 f8 7e 00 28 12 d0 e1 78 00 29 0f d0 40 1e f8 76 06 20 
			38 77 01 f0 77 fa 60 71 00 f0 60 fb 05 e0 07 20 78 77 08 20 b8 77 6e 71 ae 71 38 7c 28 5c 01 f0 
			25 fd 38 7c 40 1c c0 b2 38 74 09 28 00 d8 60 e7 04 20 00 f0 fb fe 01 f0 f9 fc 00 20 38 74 f8 73 
			b8 74 78 7e 00 28 02 d0 40 1e 78 76 f8 bd 38 7f 00 28 02 d0 40 1e 38 77 f8 bd 78 7f 00 28 05 d0 
			40 1e 78 77 b8 7f 40 1e b8 77 f8 bd 78 7c 02 28 06 d0 04 28 f9 d1 e6 70 01 f0 3c fa 20 71 f8 bd 
			38 79 01 28 fb d1 20 78 01 28 f8 d1 01 f0 ee f9 f8 bd 00 00 00 00 00 20 78 01 00 20 4c 0d 00 00 
			f8 b5 fe 4d e8 7b 08 28 08 d2 01 f0 ff f9 2a 46 e9 7b 80 32 50 54 49 1c e9 73 f8 bd f7 4c 01 26 
			00 27 20 34 08 28 5c d1 01 f0 c0 fc 21 46 60 31 0a 78 09 20 01 2a 05 d1 4b 78 00 2b 02 d1 8b 78 
			01 2b 02 d0 00 2a 11 d0 16 e0 cb 78 8a 79 db 00 1a 43 0b 79 49 79 9b 00 49 00 0b 43 1a 43 6a 74 
			e8 73 60 7c 00 28 3c d1 27 74 3a e0 4a 78 01 2a 02 d1 8a 78 01 2a 03 d0 4a 78 01 2a 0f d0 14 e0 
			cb 78 8a 79 db 00 1a 43 0b 79 49 79 9b 00 49 00 0b 43 1a 43 6a 74 e8 73 67 74 26 74 21 e0 8b 78 
			00 2b 02 d1 cb 78 01 2b 02 d0 00 2a 11 d0 16 e0 0b 79 ca 79 db 00 1a 43 4b 79 89 79 9b 00 49 00 
			0b 43 1a 43 6a 74 e8 73 60 7c 00 28 a5 d1 27 74 f8 bd 8a 78 01 2a 02 d1 ca 78 01 2a 07 d0 01 f0 
			e9 fc c6 48 c6 4d 00 7c 00 28 0f d0 36 e2 0b 79 ca 79 db 00 1a 43 4b 79 89 79 9b 00 49 00 0b 43 
			1a 43 6a 74 e8 73 67 74 26 74 f8 bd ef 70 2f 71 6f 71 af 71 ef 71 2f 72 6f 72 b8 48 41 7e 02 29 
			27 d0 01 29 2a d0 01 7f 05 29 2d d0 04 29 3a d0 03 29 3d d0 02 29 42 d0 01 29 47 d0 41 7f 00 29 
			7e d0 c0 6d 10 28 52 db 49 1e c8 00 ab 4a 40 1a b2 32 11 5c e9 70 80 18 41 78 29 71 81 78 69 71 
			c1 78 a9 71 01 79 e9 71 41 79 29 72 80 79 68 72 f4 e1 41 7c 09 01 81 76 6e 71 ef e1 81 7e 42 7c 
			11 43 81 76 6e 71 e9 e1 a8 7a e8 70 e8 7a 28 71 28 7b 68 71 68 7b a8 71 a8 7b e8 71 e8 7b 28 72 
			28 7c 68 72 da e1 41 7c 09 03 c1 86 6e 71 d5 e1 41 7c c2 8e 09 02 11 43 c1 86 6e 71 ce e1 41 7c 
			c2 8e 09 01 11 43 c1 86 6e 71 c7 e1 8b 48 c1 8e 40 7c 01 43 89 48 c1 86 00 f0 82 fa 6e 71 87 48 
			01 8f c0 8e 81 42 c3 d1 84 48 c6 77 b6 e1 0c 28 14 db 49 1e c8 00 81 4a 40 1a dc 32 11 5c e9 70 
			80 18 41 78 29 71 81 78 69 71 c1 78 a9 71 01 79 e9 71 41 79 29 72 80 79 68 72 9f e1 05 28 15 db 
			49 1e c8 00 77 4a 40 1a 11 5c e9 70 80 18 41 78 29 71 81 78 69 71 c1 78 a9 71 01 79 e9 71 00 e0 
			1b e0 41 79 29 72 80 79 68 72 87 e1 00 28 8f db 49 1e c8 00 6b 4a 40 1a 2a 32 11 5c e9 70 80 18 
			41 78 29 71 81 78 69 71 c1 78 a9 71 01 79 e9 71 41 79 29 72 80 79 68 72 70 e1 41 7c 09 29 0d d0 
			5e 48 47 76 07 77 0b 00 ff f7 b5 fc 0e 10 13 ce e8 fd fc 1e 1e 1e 1e 1e 1e fb fa 1e 04 46 47 76 
			27 77 00 20 01 f0 92 f8 a6 73 f8 bd 01 f0 02 fc f8 bd 20 7c 00 28 08 d0 a0 79 00 28 77 d0 e0 7b 
			00 28 6e d0 ae 71 e7 73 48 e1 e0 7c 01 28 01 d0 01 f0 f0 fb 49 4a 50 7b e8 70 50 78 00 28 02 d0 
			90 79 00 28 13 d0 48 49 90 6e 88 42 52 dd 49 1c 40 1a c1 17 09 0f 08 18 00 11 3d 28 00 dd 3d 20 
			d1 78 00 29 10 d0 d1 79 00 29 08 d0 0c e0 2e 71 6e 71 ae 71 ef 71 2e 72 6f 72 96 71 1e e1 3a 28 
			02 da 3a 20 d6 71 09 e0 91 78 00 29 06 d0 11 7a 00 29 03 d1 39 28 01 da 39 20 16 72 81 06 c9 0f 
			29 71 c1 06 c9 0f 69 71 01 07 c9 0f a9 71 41 07 c9 0f e9 71 81 07 c9 0f 29 72 c0 07 c0 0f 68 72 
			a0 79 00 28 0d d0 00 20 01 f0 30 f8 a6 71 e0 7b 00 28 07 d0 2f 71 6f 71 af 71 ee 71 2f 72 6e 72 
			e7 73 eb e0 2e 71 6e 71 ae 71 ee 71 2e 72 6f 72 e6 73 e3 e0 1d 49 88 42 00 da ef 70 de e0 06 e0 
			ff e7 ee 70 2e 71 2e 72 6e 72 e6 73 d6 e0 60 7a 00 28 09 d0 ee 70 2e 71 6e 71 ae 71 ee 71 2e 72 
			6e 72 40 1e 60 72 c9 e0 0c 48 0f 49 80 6e 0d 31 88 42 01 da 00 20 04 e0 0d 4a 0a 21 80 18 fe f7 
			fd fc 41 06 c9 0f e9 70 81 06 c9 0f 29 71 c1 06 c9 0f 69 71 01 07 c9 0f a9 71 0b e0 00 00 00 20 
			78 01 00 20 06 01 00 20 3f 0d 00 00 b8 0b 00 00 b4 f2 ff ff 41 07 c9 0f e9 71 81 07 c9 0f 29 72 
			c0 07 c0 0f 68 72 99 e0 20 7c 00 28 05 d1 e0 7c 02 28 01 d0 01 f0 3e fb ee 70 09 21 08 20 01 f0 
			9f fc 78 49 48 71 02 28 03 d0 01 28 03 d0 6e 71 84 e0 2e 71 82 e0 2e 71 6e 71 7f e0 20 7c 00 28 
			1e d0 a0 7a 80 06 c0 0f 28 71 a0 7a c0 06 c0 0f 68 71 a0 7a 00 07 c0 0f a8 71 a0 7a 40 07 03 e0 
			65 e0 53 e0 4c e0 28 e0 c0 0f e8 71 a0 7a 80 07 c0 0f 28 72 a0 7a c0 07 c0 0f 68 72 67 72 5d e0 
			e0 7c 03 28 01 d0 01 f0 05 fb 5e 48 40 78 00 28 04 d0 af 71 ef 71 2f 72 6f 72 4f e0 20 7d 02 28 
			4c d0 01 28 04 d0 af 71 ef 71 2e 72 6e 72 45 e0 af 71 ef 71 2e 72 6f 72 40 e0 52 48 06 70 60 7c 
			00 28 04 d0 4f 49 4f 73 40 1e 60 74 14 e0 20 7c 01 28 0e d0 e0 7c 04 28 01 d0 01 f0 db fa 2e 70 
			6f 70 ae 70 47 48 40 7b e8 70 6e 71 2e 72 6e 72 24 e0 44 48 40 7b e8 70 6e 71 2e 72 6e 72 1d e0 
			40 48 03 21 41 76 2e 71 ae 71 17 e0 3d 49 c8 7e 00 28 13 d0 e2 78 00 2a 10 d0 40 1e c8 76 06 20 
			08 77 00 f0 87 ff 60 71 00 f0 70 f8 06 e0 35 48 07 21 41 77 08 21 81 77 6e 71 ae 71 31 4d 32 48 
			29 7c 40 5c 01 f0 32 fa 28 7c 40 1c c0 b2 28 74 09 28 00 d8 9c e6 04 20 00 f0 08 fc 01 f0 06 fa 
			2f 74 ef 73 af 74 6f 72 68 7e 00 28 02 d0 40 1e 68 76 f8 bd 28 7f 00 28 02 d0 40 1e 28 77 f8 bd 
			68 7f 00 28 05 d0 40 1e 68 77 a8 7f 40 1e a8 77 f8 bd 68 7c 01 28 2a d0 02 28 09 d0 03 28 2b d0 
			04 21 04 28 13 d0 20 7c 00 28 f1 d1 e1 74 f8 bd 68 79 01 28 fb d1 20 78 01 28 01 d1 00 f0 f6 fe 
			6f 71 20 7c 00 28 f2 d1 03 20 e0 74 f8 bd 20 7c 00 28 07 d1 0c 48 c0 78 00 28 02 d0 02 20 e0 74 
			00 e0 e1 74 e6 70 00 f0 25 ff 20 71 f8 bd 20 7c 00 28 fb d1 e6 74 f8 bd 20 7c 00 28 fb d1 e6 74 
			f8 bd 00 00 00 00 00 20 78 01 00 20 28 48 00 78 40 02 28 49 09 78 49 00 08 43 27 49 08 80 24 48 
			00 78 40 06 c0 0f 25 49 48 71 21 48 00 78 80 06 c0 0f c8 72 1e 48 00 78 c0 06 c0 0f 08 72 1c 48 
			00 78 00 07 c0 0f 08 74 19 48 00 78 40 07 c0 0f 88 73 17 48 00 78 80 07 c0 0f 48 73 14 48 00 78 
			c0 07 c0 0f c8 71 13 48 00 78 40 06 c0 0f c8 70 10 48 00 78 80 06 c0 0f 08 73 0e 48 00 78 c0 06 
			c0 0f 08 71 0b 48 00 78 00 07 c0 0f 88 72 09 48 00 78 40 07 c0 0f 48 72 06 48 00 78 80 07 c0 0f 
			c8 73 04 48 00 78 c0 07 c0 0f 88 71 70 47 00 00 24 00 00 20 25 00 00 20 38 00 00 20 78 01 00 20 
			03 48 00 88 03 49 08 40 01 49 08 80 70 47 00 00 36 00 00 20 fe fe 00 00 10 b5 01 22 20 4b d1 02 
			19 60 0b 01 1f 49 02 28 2a d0 0c 68 9c 43 0c 60 01 23 9b 03 03 28 27 d0 0c 68 9c 43 0c 60 01 23 
			5b 03 04 28 24 d0 0c 68 9c 43 0c 60 01 23 1b 03 05 28 21 d0 0c 68 9c 43 0c 60 0b 68 f0 24 00 07 
			a3 43 00 0e 03 43 0b 60 08 68 02 23 18 43 08 60 08 68 10 43 08 60 08 68 c0 07 fc d1 48 68 10 bd 
			0c 68 1c 43 0c 60 d3 e7 0c 68 1c 43 0c 60 d6 e7 0c 68 1c 43 0c 60 d9 e7 0c 68 1c 43 0c 60 dc e7 
			00 e1 00 e0 00 40 00 40 70 47 70 47 1c b5 16 a0 00 68 01 90 00 20 00 90 01 aa 01 21 0f 20 fe f7 
			dc ff 12 20 00 f0 f2 fa 6a 46 01 21 0f 20 fe f7 31 ff 00 24 68 46 00 78 c0 06 0f d4 2d 20 00 f0 
			e5 fa 01 aa 01 21 0f 20 fe f7 c7 ff 12 20 00 f0 dd fa 6a 46 01 21 0f 20 fe f7 1c ff 64 1c e4 b2 
			0f 2c e7 d3 1c bd 00 00 12 00 00 00 1c b5 16 a0 00 68 01 90 00 20 00 90 01 aa 01 21 0f 20 fe f7 
			ac ff 12 20 00 f0 c2 fa 6a 46 01 21 0f 20 fe f7 01 ff 00 24 68 46 00 78 c0 06 0f d4 2d 20 00 f0 
			b5 fa 01 aa 01 21 0f 20 fe f7 97 ff 12 20 00 f0 ad fa 6a 46 01 21 0f 20 fe f7 ec fe 64 1c e4 b2 
			0f 2c e7 d3 1c bd 00 00 1a 00 00 00 02 48 c1 68 02 22 11 43 c1 60 70 47 00 50 00 40 fe b5 01 46 
			00 20 2f 4d 04 29 0a d0 10 29 35 d0 02 29 51 d0 1c 29 03 d1 e8 7a 29 7b 09 02 08 43 fe bd 00 20 
			ff f7 3a ff 0a 21 fe f7 a9 fa 26 49 88 42 19 da 00 24 6e 46 00 20 ff f7 2f ff 0a 21 fe f7 9e fa 
			a1 00 70 50 64 1c e4 b2 03 2c f3 d3 01 99 00 98 40 18 02 99 40 18 fe f7 9f fc 1b 49 fe f7 38 fb 
			fe f7 c8 fc 19 49 08 60 e8 70 01 12 29 71 14 4a 20 32 d0 70 11 71 fe bd 01 20 ff f7 0d ff fe f7 
			8b fc 13 49 fe f7 e7 fa 04 46 20 46 fe f7 b2 fc 10 49 08 60 68 71 01 12 a9 71 01 14 e9 71 00 0e 
			28 72 0d 49 20 46 fe f7 13 fb fe f7 a3 fc 0b 49 08 60 fe bd 68 7a a9 7a 09 02 08 43 fe bd 00 00 
			89 01 00 20 b8 0b 00 00 00 00 40 40 60 01 00 20 00 00 fa 43 64 01 00 20 00 00 7a 44 60 00 00 20 
			30 b5 03 20 ff f7 d8 fe 0d 4d 0e 4c a8 42 09 db 04 20 ff f7 d1 fe a8 42 04 db 02 20 ff f7 cc fe 
			a8 42 03 da 20 78 40 1c 20 70 01 e0 00 20 20 70 20 78 09 28 01 d9 01 20 30 bd 00 20 30 bd 00 00 
			41 08 00 00 2e 00 00 20 10 b5 04 46 00 2c 02 d0 00 20 00 f0 6f ff 01 21 10 20 ff f7 19 f8 01 22 
			0f 49 10 04 08 60 0f 48 01 68 80 23 99 43 01 60 0d 49 08 69 10 43 08 61 08 69 04 22 90 43 08 61 
			08 69 ff 22 81 32 90 43 80 30 08 61 08 69 4a 15 10 43 08 61 00 2c 02 d0 01 20 00 f0 4b ff 10 bd 
			00 e1 00 e0 00 70 00 40 00 50 00 40 70 b5 04 46 00 2c 02 d0 00 20 00 f0 3d ff 01 21 0e 20 fe f7 
			e7 ff 01 23 0f 49 98 03 08 60 0f 48 01 68 42 15 91 43 01 60 0d 49 08 68 04 25 a8 43 08 60 08 68 
			18 43 08 60 08 68 ff 23 81 33 98 43 80 30 08 60 08 68 10 43 08 60 00 2c 02 d0 01 20 00 f0 1a ff 
			70 bd 00 00 00 e1 00 e0 00 70 00 40 00 50 00 40 f0 b5 8f b0 00 20 02 90 00 25 01 26 00 24 02 aa 
			02 21 25 20 fe f7 d6 fd 69 46 08 7a 49 7a 00 02 08 43 fe f7 e1 fb 9b 4a 9b 4b fe f7 55 fb fe f7 
			03 fc a7 00 0b a9 c8 51 00 f0 52 f9 14 20 00 f0 7d f9 0b a8 c1 59 0b 98 08 1a 00 d5 40 42 64 28 
			0c dd 01 2e 0a d1 00 2c 08 d0 6d 1c ed b2 02 2d 02 d3 00 25 0b 91 00 26 64 1e e4 b2 64 1c e4 b2 
			03 2c cc d3 0c 99 0b 98 40 18 0d 99 40 18 fe f7 93 fb 86 49 fe f7 2c fa fe f7 bc fb 05 46 84 48 
			04 78 64 20 44 43 26 46 c8 3e 67 1b 00 d5 7f 42 a5 42 01 dd 25 46 60 e0 c8 2f 5e dd 20 46 fe f7 
			87 fb 7c 4a 7c 4b fe f7 0f fb 00 90 01 91 38 46 fe f7 7e fb 01 9b 00 9a fe f7 ee fb 01 d8 35 46 
			4b e0 76 49 76 48 8c 42 06 d1 01 68 7d 20 80 01 81 42 42 dd 35 46 40 e0 7d 21 49 01 71 4a 8c 42 
			04 d1 00 68 90 42 38 dd 35 46 36 e0 6e 4b 9c 42 04 d1 00 68 90 42 30 dd 35 46 2e e0 6b 4a 94 42 
			04 d1 00 68 88 42 28 dd 35 46 26 e0 68 4a 94 42 04 d1 00 68 88 42 20 dd 35 46 1e e0 4b 22 52 01 
			94 42 04 d1 00 68 88 42 17 dd 35 46 15 e0 7d 20 00 01 84 42 01 d1 35 46 0f e0 5e 48 84 42 01 d1 
			35 46 0a e0 af 20 c0 00 84 42 01 d1 35 46 04 e0 7d 20 c0 00 84 42 00 d1 35 46 00 26 01 27 01 24 
			09 20 ff f7 99 fd 0a 21 fe f7 08 f9 a2 00 03 a9 88 50 4e 49 88 42 09 da 01 2f 07 d1 76 1c f6 b2 
			02 2e 01 d3 00 26 00 27 64 1e e4 b2 64 1c e4 b2 04 2c e5 d3 00 26 01 27 01 24 07 20 ff f7 7c fd 
			0a 21 fe f7 eb f8 a2 00 07 a9 88 50 3b 49 88 42 09 da 01 2f 07 d1 76 1c f6 b2 02 2e 01 d3 00 26 
			00 27 64 1e e4 b2 64 1c e4 b2 04 2c e5 d3 09 99 08 98 40 18 0a 99 40 18 fe f7 de fa 2b 4c 21 46 
			fe f7 76 f9 fe f7 06 fb 07 46 05 99 04 98 40 18 06 99 40 18 fe f7 d0 fa 21 46 fe f7 69 f9 fe f7 
			f9 fa 06 46 2c 48 00 78 02 28 0e d1 28 48 86 42 02 db 40 00 87 42 08 da 28 48 29 49 00 78 09 78 
			08 43 02 d1 54 20 00 f0 fb fe 26 48 46 71 31 12 81 71 28 46 fe f7 b0 fa fe f7 1a fb 15 4a 22 4b 
			fe f7 42 fa 04 46 21 48 0d 46 00 68 30 1a fe f7 a3 fa 01 21 c9 43 fe f7 79 f9 06 46 38 46 fe f7 
			9b fa 00 21 c9 43 fe f7 71 f9 31 46 fe f7 eb f8 fe f7 fe fa 22 46 2b 46 fe f7 18 fa fe f7 d4 fa 
			0f b0 f0 bd 1f 85 eb 51 b8 1e f1 3f 00 00 40 40 2a 00 00 20 33 33 33 33 33 33 c3 3f 88 13 00 00 
			60 00 00 20 70 17 00 00 ac 0d 00 00 b8 0b 00 00 c4 09 00 00 dc 05 00 00 30 00 00 20 26 00 00 20 
			0e 00 00 20 a9 01 00 20 33 33 b3 3f 68 00 00 20 08 b5 0a 20 00 90 01 e0 00 f0 06 f8 00 98 41 1e 
			00 91 f9 d2 08 bd 00 00 08 b5 04 48 00 90 00 e0 00 bf 00 98 41 1e 00 91 fa d2 08 bd ed 08 00 00 
			08 b5 2c 20 00 90 00 e0 00 bf 00 98 41 1e 00 91 fa d2 08 bd 08 b5 04 48 00 90 00 e0 00 bf 00 98 
			41 1e 00 91 fa d2 08 bd 37 02 00 00 00 b5 02 46 03 e0 ff f7 ef ff 52 1e d2 b2 00 2a f9 d1 00 bd 
			70 47 00 00 88 b0 00 20 07 90 00 25 06 90 05 90 00 26 04 90 03 90 02 90 01 90 f9 4c 21 7c 20 46 
			20 38 02 29 21 d0 e1 21 89 00 81 87 e1 21 f4 48 49 01 20 38 41 87 f3 49 01 67 81 67 00 f0 f8 ff 
			ef 4f 20 3f 78 6f 00 28 13 d0 38 6f 00 28 5b d0 f8 6e 00 28 70 d0 b8 6f 00 28 6e d0 f8 6f 00 28 
			6c d0 20 7a 00 28 6a d0 d2 e2 c3 21 c9 00 81 87 dc e7 58 20 00 f0 98 fe a1 79 00 29 40 d1 1f 28 
			12 d0 00 28 16 d0 0a 28 07 d0 0b 28 05 d0 09 28 03 d0 79 8f dc 4a 91 42 13 d9 20 7c 02 28 0c d0 
			3b 20 3b 21 a1 70 15 e0 00 20 00 f0 bf fa 01 20 a0 71 25 e0 00 f0 24 fe 22 e0 32 20 32 21 a1 70 
			08 e0 08 28 0a d0 21 7c 02 29 0f d0 40 1c 0a 21 48 43 a0 70 61 7a 00 29 0c d0 11 e0 20 7c 02 28 
			02 d0 50 20 a0 70 f5 e7 28 20 fb e7 40 1c 81 00 40 18 ee e7 c1 b2 a2 78 e0 7a 00 f0 d5 fd 60 72 
			7d 20 00 01 78 67 83 e2 bd 48 20 38 00 7d ff f7 d5 fc 07 46 a0 79 00 28 46 d1 7d 20 00 01 c7 42 
			0e da 06 98 40 1c c0 b2 06 90 06 98 03 28 09 d9 54 20 00 f0 d5 fd 05 e0 b8 e0 f4 e1 33 e2 4e e2 
			00 20 06 90 20 7c 02 28 0a d0 b0 48 87 42 14 dd 76 1c f6 b2 07 2e 11 d9 59 20 00 f0 c1 fd 0d e0 
			ab 48 87 42 07 dd 76 1c f6 b2 07 2e 06 d9 59 20 00 f0 b6 fd 02 e0 00 26 00 e0 00 26 a0 49 20 39 
			08 7b 01 28 16 d0 02 28 51 d0 00 20 05 21 40 18 05 28 09 d9 04 98 40 1c c0 b2 04 90 04 98 05 28 
			02 d9 5a 20 00 f0 9c fd 7d 21 95 48 c9 00 20 38 01 67 2d e2 88 6e 97 49 88 42 01 dd 05 20 18 e0 
			23 21 c9 01 88 42 01 dd 04 20 12 e0 91 49 14 39 88 42 01 dd 03 20 0c e0 8e 49 1e 39 88 42 01 dd 
			02 20 06 e0 8b 49 28 39 88 42 01 dd 01 20 00 e0 00 20 89 49 8f 42 01 dd 00 21 c8 e7 af 21 c9 00 
			8f 42 01 dd 01 21 c2 e7 83 49 fa 39 8f 42 01 dd 02 21 bc e7 4b 21 09 01 8f 42 01 dd 03 21 b6 e7 
			7e 49 8f 42 01 dd 04 21 b1 e7 05 21 af e7 88 6e 78 49 88 42 01 dd 05 20 18 e0 76 49 49 1f 88 42 
			01 dd 04 20 12 e0 73 49 14 39 88 42 01 dd 03 20 0c e0 70 49 1e 39 88 42 01 dd 02 20 06 e0 6d 49 
			28 39 88 42 01 dd 01 20 00 e0 00 20 6a 49 64 31 8f 42 01 dd 00 21 8a e7 67 49 32 39 8f 42 01 dd 
			01 21 84 e7 af 21 c9 00 8f 42 01 dd 02 21 7e e7 62 49 c8 31 8f 42 01 dd 03 21 78 e7 4b 21 09 01 
			8f 42 01 dd 04 21 72 e7 05 21 70 e7 f8 7c ff f7 05 fc b8 66 38 7d ff f7 01 fc ff f7 f9 fc 78 66 
			a0 79 00 28 73 d1 21 7c 02 29 03 d0 b8 8f 00 28 1d d0 21 e0 b8 8f 00 28 09 d0 0f 22 92 01 90 42 
			0b d2 e0 7a 1e 28 17 d9 1e 20 e0 72 14 e0 e0 7a 32 28 11 d9 32 20 e0 72 0e e0 48 4a a0 32 90 42 
			0a d2 e0 7a 28 28 07 d9 28 20 e0 72 04 e0 e0 7a 32 28 01 d9 32 20 e0 72 20 7b 00 28 12 d1 3d 4a 
			b8 6e 28 3a 90 42 05 dd e0 7a 32 28 0a d9 32 20 e0 72 07 e0 3a 4a 90 42 04 dd e0 7a 32 28 01 d9 
			32 20 e0 72 02 29 31 d1 f8 6d 01 46 78 39 28 29 08 d2 30 48 8c 38 b8 64 f8 64 2e 48 0f 38 38 65 
			78 65 0f e0 01 46 32 39 46 29 06 d2 2c 48 14 38 38 65 28 48 46 38 78 65 04 e0 32 28 02 da 28 48 
			14 38 78 65 39 6c b8 6e 88 42 11 dd 25 4a 39 6e 91 42 0d db 24 4a 91 42 0a da 6d 1c ed b2 03 2d 
			04 d3 e0 7a 28 28 01 d9 28 20 e0 72 7f e0 b3 e0 79 6c 88 42 10 dd 1d 4a 39 6e 91 42 0c db 19 4a 
			91 42 09 da 6d 1c ed b2 03 2d 70 d3 e0 7a 1e 28 6d d9 1e 20 e0 72 6a e0 b9 6c 88 42 2a dd 14 4a 
			39 6e 91 42 26 db 11 4a 91 42 23 da 6d 1c ed b2 03 2d 5c d3 e0 7a 19 28 59 d9 19 20 e0 72 56 e0 
			20 00 00 20 20 4e 00 00 1e 1c 00 00 4c 1d 00 00 ec 2c 00 00 8a 11 00 00 0e 06 00 00 4c 04 00 00 
			68 10 00 00 6c 20 00 00 04 29 00 00 9c 18 00 00 b4 14 00 00 f9 6c 88 42 10 dd 77 4a 39 6e 91 42 
			0c db 76 4a 91 42 09 da 6d 1c ed b2 03 2d 2e d3 e0 7a 14 28 2b d9 14 20 e0 72 28 e0 39 6d 88 42 
			10 dd 6f 4a 39 6e 91 42 0c db 6b 4a 91 42 09 da 6d 1c ed b2 03 2d 1a d3 e1 7a b8 6d 81 42 16 dd 
			e0 72 14 e0 79 6d 88 42 10 dd 66 49 38 6e 88 42 0c db 63 49 88 42 09 da 6d 1c ed b2 03 2d 06 d3 
			e0 7a 0a 28 03 d9 0a 20 e0 72 00 e0 00 25 20 7d 02 28 06 d1 58 48 b9 6e 78 38 81 42 01 dd 01 20 
			f8 70 60 7a 00 28 05 d1 a2 78 61 78 e0 7a 00 f0 eb fb 60 72 20 7d 02 28 07 d1 4f 49 b8 6e 82 31 
			88 42 02 dd 5a 20 00 f0 fb fb 4b 49 b8 6e c3 31 88 42 02 dd 5a 20 00 f0 f3 fb 47 49 b8 6e b9 31 
			88 42 0a dd 07 98 40 1c c0 b2 07 90 07 98 05 28 05 d9 5a 20 00 f0 e4 fb 01 e0 00 20 07 90 ff 20 
			f5 30 f8 66 74 e0 b8 7d ff f7 c8 fa a1 79 00 29 35 d1 ff 21 b3 31 88 42 0b dd 01 99 49 1c c9 b2 
			01 91 01 99 02 29 19 d9 03 21 01 91 01 21 f9 70 14 e0 ff 21 a5 31 88 42 0d dd 00 21 01 91 02 99 
			49 1c c9 b2 02 91 02 99 02 29 07 d9 03 21 02 91 01 21 b9 70 02 e0 00 21 02 91 01 91 ff 21 c4 31 
			88 42 0a d3 05 98 40 1c c0 b2 05 90 05 98 02 28 05 d9 5c 20 00 f0 a4 fb 01 e0 00 20 05 90 ff 20 
			f5 30 b8 67 34 e0 a0 79 00 28 03 d0 03 98 00 28 0d d0 11 e0 ff f7 f4 fa 00 28 04 d0 00 20 00 f0 
			35 f8 01 20 a0 71 19 20 40 01 f8 67 20 e0 5d 20 00 f0 ea fb 01 20 03 90 13 48 f8 67 18 e0 78 8f 
			a1 79 08 43 02 d1 5a 20 00 f0 7a fb b8 7b 00 28 03 d0 59 20 00 f0 74 fb 08 e0 78 7a 00 28 02 d1 
			a0 7c 01 28 02 d9 54 20 00 f0 6a fb 14 20 20 72 2f 20 ff f7 eb fc 11 e5 cc 10 00 00 b4 14 00 00 
			e4 0c 00 00 fc 08 00 00 10 27 00 00 00 28 03 d0 04 49 01 20 08 70 70 47 03 48 c1 68 02 22 91 43 
			c1 60 70 47 0b 00 00 20 00 50 00 40 06 48 c1 68 02 22 91 43 c1 60 c1 68 49 08 49 00 c1 60 c1 68 
			04 22 11 43 c1 60 70 47 00 50 00 40 02 48 40 69 40 06 c0 0f 70 47 00 00 00 50 00 40 02 48 40 68 
			40 06 c0 0f 70 47 00 00 00 50 00 40 03 48 00 78 00 28 01 d0 00 20 70 47 01 20 70 47 0b 00 00 20 
			00 b5 09 20 ff f7 58 f9 01 49 08 60 00 bd 00 00 5c 01 00 20 02 48 80 68 40 06 40 0e 70 47 00 00 
			00 10 00 40 10 b5 10 48 41 69 80 23 99 43 41 61 81 69 81 61 0d 49 0a 68 1c 04 a2 43 0a 60 0c 4a 
			01 21 11 60 01 68 fe 22 91 43 1c 31 01 60 41 69 20 22 11 43 41 61 41 69 10 22 11 43 41 61 41 69 
			19 43 41 61 10 bd 00 00 00 30 00 40 00 70 00 40 00 e1 00 e0 08 b5 00 f0 ed f9 00 f0 27 fc 00 f0 
			ea f9 ff f7 cf ff 00 20 ff f7 90 fa 01 20 00 f0 d1 f9 53 20 00 f0 ae fb 01 07 09 0f 40 06 40 0f 
			00 28 55 d0 01 28 55 d0 02 28 55 d0 03 28 55 d0 57 25 df 4c 00 29 53 d0 01 29 53 d0 02 29 53 d0 
			03 29 55 d0 04 29 57 d0 0a 20 e0 65 00 f0 e2 fa 00 f0 f8 fa 00 20 00 f0 ad f9 00 21 08 46 fe f7 
			35 fa 01 21 0b 20 fe f7 31 fa 01 21 05 20 fe f7 2d fa 01 21 07 20 fe f7 29 fa 00 20 ff f7 24 fa 
			01 20 00 f0 97 f9 ff f7 2b fc 04 20 ff f7 86 f9 10 20 ff f7 83 f9 00 f0 ad f9 ff f7 e9 fb ff f7 
			e7 fb ff f7 e5 fb 00 f0 e7 fa 00 28 eb d0 00 f0 27 fc bf 4c 00 26 20 34 00 f0 2a fc bc 4f 78 7a 
			00 28 01 d0 00 f0 8c fa f8 7f 01 28 19 d0 1b e0 0a 25 ae e7 3c 25 ac e7 50 25 aa e7 57 25 a8 e7 
			0a 20 b2 e7 3c 20 b0 e7 82 20 01 21 21 73 ac e7 aa 20 01 21 21 73 a8 e7 ff 20 05 30 02 21 21 73 
			a3 e7 b8 7f 01 28 15 d0 20 7c 00 28 12 d0 04 20 ff f7 44 f9 10 20 ff f7 41 f9 00 f0 6b f9 ff f7 
			a7 fb ff f7 a5 fb ff f7 a3 fb 38 78 00 28 c3 d1 e6 71 c1 e7 01 27 27 70 ff f7 c6 f8 52 20 00 f0 
			a3 fa 00 90 ff f7 22 f9 a7 74 00 98 00 28 01 d1 00 f0 46 fa 00 f0 dc fb 5e 20 00 f0 95 fa 07 46 
			02 2f 01 d0 00 f0 3c fa 00 f0 d2 fb ff f7 80 fb 00 f0 ce fb 20 7c 00 28 04 d0 01 28 07 d0 02 28 
			0a d0 0d e0 13 20 00 f0 7f fa 07 46 08 e0 19 20 00 f0 7a fa 07 46 03 e0 14 20 00 f0 75 fa 07 46 
			02 2f 01 d0 00 f0 1c fa 00 f0 b2 fb 80 4f 04 20 f8 74 10 20 38 75 1c 20 78 75 02 20 b8 75 01 20 
			38 76 00 f0 a5 fb f8 7c ff f7 e8 f8 b8 66 78 66 ff f7 4e fb 14 27 55 2d 0c d9 20 7c 02 28 05 d0 
			a7 72 e7 72 72 49 01 20 48 70 23 e0 0a 20 a0 72 e0 72 f7 e7 4b 2d 0a d9 20 7c 02 28 03 d0 1e 20 
			a0 72 e0 72 16 e0 0f 20 a0 72 e0 72 12 e0 32 2d 0a d9 20 7c 02 28 03 d0 32 20 a0 72 e0 72 09 e0 
			19 20 a0 72 e0 72 05 e0 20 7c 02 28 02 d0 3b 20 a0 72 e0 72 ff f7 1c fb 5d 48 80 7d ff f7 ae f8 
			5b 48 c0 6d 32 28 24 da 26 73 20 7c 02 28 07 d0 32 2d 15 d9 e0 7a 14 28 18 d9 a7 72 e7 72 15 e0 
			32 2d 06 d9 e0 7a 0a 28 10 d9 0a 20 a0 72 e0 72 0c e0 e0 7a 0e 28 09 d9 0e 20 a0 72 e0 72 05 e0 
			e0 7a 1c 28 02 d9 1c 20 a0 72 e0 72 02 20 20 75 6b e0 28 21 78 28 34 da 26 73 20 7c 02 28 07 d0 
			4b 2d 1d d9 e0 7a 14 28 28 d9 a7 72 e7 72 25 e0 4b 2d 06 d9 e0 7a 0a 28 20 d9 0a 20 a0 72 e0 72 
			1c e0 32 2d 06 d9 e0 7a 0f 28 17 d9 0f 20 a0 72 e0 72 13 e0 e0 7a 14 28 10 d9 a7 72 e7 72 0d e0 
			32 2d 06 d9 e0 7a 1e 28 08 d9 1e 20 a0 72 e0 72 04 e0 e0 7a 28 28 01 d9 a1 72 e1 72 02 20 20 75 
			33 e0 a0 28 31 da 26 73 20 7c 02 28 07 d0 4b 2d 1d d9 e0 7a 14 28 28 d9 a7 72 e7 72 25 e0 4b 2d 
			06 d9 e0 7a 0a 28 20 d9 0a 20 a0 72 e0 72 1c e0 32 2d 05 d9 e0 7a 14 28 17 d9 a7 72 e7 72 14 e0 
			e0 7a 1e 28 11 d9 1e 20 a0 72 e0 72 0d e0 32 2d 05 d9 e0 7a 28 28 08 d9 a1 72 e1 72 05 e0 e0 7a 
			3b 28 02 d9 3b 20 a0 72 e0 72 ff f7 09 fe 10 4d 01 20 68 73 0a e0 00 f0 cb fa 68 7a 00 28 02 d1 
			a0 7c 01 28 02 d9 54 20 00 f0 1a f9 ff f7 ee fd 01 28 f0 d0 00 f0 bc fa 20 7c 02 28 05 d0 fe f7 
			c5 ff 00 f0 b5 fa ff f7 9d fa fe f7 8f ff f8 e7 00 00 00 20 06 4a 00 28 11 78 01 d0 00 29 05 d0 
			00 28 02 d1 00 29 00 d0 10 70 70 47 10 70 70 47 70 01 00 20 70 47 00 b5 ff f7 a8 fd 00 f0 a4 f8 
			00 f0 62 f8 00 f0 72 f8 00 f0 30 f8 fe f7 6d ff 00 bd 00 00 70 b5 08 20 fe f7 1e ff 0a 21 fd f7 
			8d fa 04 46 09 20 fe f7 17 ff 0a 21 fd f7 86 fa 05 46 03 20 fe f7 10 ff 0a 21 fd f7 7f fa 06 46 
			02 20 fe f7 09 ff 0a 21 fd f7 78 fa 06 49 cc 71 22 12 0a 72 4d 72 2a 12 8a 72 ce 72 32 12 0a 73 
			48 73 00 12 88 73 70 bd a9 01 00 20 06 48 01 69 04 22 91 43 01 61 01 69 30 22 91 43 01 61 01 69 
			01 22 11 43 01 61 70 47 00 50 00 40 06 48 01 69 49 08 49 00 01 61 01 69 04 22 11 43 01 61 01 69 
			02 22 91 43 01 61 70 47 00 50 00 40 05 49 02 22 00 28 03 d0 08 69 10 43 08 61 70 47 08 69 90 43 
			08 61 70 47 00 50 00 40 07 48 01 68 04 22 91 43 01 60 01 68 30 22 91 43 10 31 01 60 01 68 01 22 
			11 43 01 60 70 47 00 00 00 50 00 40 06 48 41 69 04 22 91 43 41 61 41 69 30 22 91 43 41 61 41 69 
			01 22 11 43 41 61 70 47 00 50 00 40 06 48 41 69 02 22 91 43 41 61 41 69 49 08 49 00 41 61 41 69 
			04 22 11 43 41 61 70 47 00 50 00 40 05 49 02 22 00 28 03 d0 48 69 10 43 48 61 70 47 48 69 90 43 
			48 61 70 47 00 50 00 40 07 48 41 68 04 22 91 43 41 60 41 68 30 22 91 43 20 31 41 60 41 68 01 22 
			11 43 41 60 70 47 00 00 00 50 00 40 06 48 41 68 02 22 91 43 41 60 41 68 49 08 49 00 41 60 41 68 
			04 22 11 43 41 60 70 47 00 50 00 40 05 49 02 22 00 28 03 d0 48 68 10 43 48 60 70 47 48 68 90 43 
			48 60 70 47 00 50 00 40 30 b5 0c 4b 9c 7a dd 7a 85 42 00 d9 d8 72 59 70 9a 70 91 42 00 d2 0a 46 
			d8 7a 90 42 01 d9 9a 72 01 e0 d8 7a 98 72 98 7a 84 42 01 d0 05 20 30 bd 00 20 30 bd 20 00 00 20 
			10 b5 04 46 00 f0 a4 f9 00 20 ff f7 9f fc ff f7 7d ff 20 46 00 f0 58 f8 00 f0 02 f8 10 bd 00 00 
			03 49 02 48 c8 60 bf f3 4f 8f fe e7 04 00 fa 05 00 ed 00 e0 10 b5 06 49 88 7c 02 28 03 d0 01 28 
			02 d0 ff f7 ed ff 10 bd 02 20 88 74 10 bd 00 00 20 00 00 20 10 b5 00 24 00 20 ff f7 cb fe ff f7 
			25 ff 00 20 ff f7 32 ff 01 20 ff f7 4f f9 01 20 ff f7 2c ff 03 20 ff f7 49 f9 64 1c e4 b2 1e 2c 
			ef d3 10 bd 0a 49 80 20 08 60 0a 48 41 68 7d 21 c9 01 41 60 01 68 40 22 11 43 01 60 01 68 20 22 
			11 43 01 60 01 68 49 08 49 00 01 60 70 47 00 00 00 e1 00 e0 00 10 00 40 02 48 00 68 c0 07 c0 0f 
			70 47 00 00 00 10 00 40 f8 b5 05 46 00 26 00 f0 3f f9 37 4f 00 20 b8 72 ff f7 58 ff ff f7 00 f9 
			00 20 ff f7 63 ff ff f7 e3 f8 01 20 ff f7 5e ff 00 24 78 7a 00 28 03 d0 58 2d 01 d1 ff f7 06 ff 
			00 f0 26 f9 b8 7a 00 28 fc d0 00 f0 21 f9 06 20 01 1b 28 46 c8 40 c0 07 c0 0f ff f7 47 ff 00 20 
			b8 72 64 1c e4 b2 07 2c e3 d3 00 f0 11 f9 00 24 78 7a 00 28 03 d0 58 2d 01 d1 ff f7 e7 fe 00 f0 
			07 f9 b8 7a 00 28 fc d0 00 f0 02 f9 00 2c 03 d1 ff f7 0a ff ff f7 c4 f8 00 20 b8 72 ff f7 1e fc 
			06 2c 1f d0 00 2c 06 d0 06 2c 04 d2 05 21 09 1b 88 40 30 43 c6 b2 64 1c e4 b2 07 2c d8 d3 00 f0 
			e7 f8 b8 7a 00 28 fc d0 00 f0 e2 f8 ff f7 fe fe 00 20 b8 72 ff f7 8c f8 ff f7 8a f8 00 f0 d8 f8 
			30 46 f8 bd 39 7e 00 29 e5 d1 f8 75 e3 e7 00 00 00 00 00 20 f8 b5 05 46 00 26 00 f0 c9 f8 32 48 
			00 27 87 72 ff f7 e2 fe ff f7 8a f8 00 20 ff f7 ed fe ff f7 6d f8 01 20 ff f7 e8 fe 00 24 2a 4f 
			78 7a 00 28 03 d0 58 2d 01 d1 ff f7 8f fe 00 f0 af f8 b8 7a 00 28 fc d0 00 f0 aa f8 06 20 01 1b 
			28 46 c8 40 c0 07 c0 0f ff f7 d0 fe 00 20 b8 72 64 1c e4 b2 07 2c e3 d3 00 f0 9a f8 00 24 78 7a 
			00 28 03 d0 58 2d 01 d1 ff f7 70 fe 00 f0 90 f8 b8 7a 00 28 fc d0 00 f0 8b f8 00 2c 03 d1 ff f7 
			93 fe ff f7 4d f8 00 20 b8 72 ff f7 a7 fb 06 21 09 1b 88 40 30 43 c6 b2 64 1c e4 b2 07 2c de d3 
			00 f0 76 f8 b8 7a 00 28 fc d0 00 f0 71 f8 ff f7 8d fe 00 20 b8 72 ff f7 1b f8 ff f7 19 f8 00 f0 
			67 f8 30 46 f8 bd 00 00 00 00 00 20 30 b5 1a 4a 00 21 51 72 51 73 91 73 d1 73 18 48 01 23 03 70 
			41 70 81 70 11 74 91 74 11 76 91 70 d1 70 51 76 91 76 03 25 d5 76 11 77 51 77 91 77 d1 86 48 1e 
			10 87 d1 77 10 46 20 30 01 70 32 24 44 70 84 70 c1 70 81 71 41 72 84 72 c4 72 03 73 43 73 81 73 
			c1 73 02 24 04 74 45 74 81 74 04 24 c4 74 01 75 13 73 d1 72 30 bd 00 00 00 00 00 20 78 01 00 20 
			30 b5 0d 46 fe f7 b8 fc 04 46 28 46 fe f7 b4 fc 0a 49 0b 78 02 2b 07 d0 20 1a 7d 21 c9 00 4a 00 
			88 42 04 da 00 20 30 bd 21 1a 08 1a f5 e7 90 42 01 dd 02 20 30 bd 01 20 30 bd 00 00 30 00 00 20 
			02 48 5a 21 01 61 80 21 01 61 70 47 00 70 00 40 03 48 5a 21 01 61 01 69 40 22 11 43 01 61 70 47 
			00 70 00 40 e4 30 00 00 00 00 00 20 78 01 00 00 f8 07 00 00 3c 31 00 00 78 01 00 20 18 05 00 00 
			00 0f 00 00 01 40 23 68 10 1a cc 04 4b 62 11 04 5a 7b 04 32 0f 02 2c fa 1a 01 02 19 06 19 01 49 
			0f 29 10 79 0e 59 0c 49 0e 69 2a 29 07 39 03 29 05 49 2f 59 42 29 0e 29 0d 59 2a 49 14 09 1b 2a 
			49 6b 39 1f 59 33 39 2a 49 29 f9 2a 59 78 79 8d 79 38 c9 2a 41 23 d8 0e 03 12 d0 07 00 02 00 07 
			01 01 05 00 09 34 55 34
		];
	};
};

&pm6150_vadc {
	usb_supplementary_temp_adc {
		reg = <ADC_AMUX_THM3_PU2>;
		label = "usb_supplementary_temp_adc";
		qcom,pre-scaling = <1 1>;
		qcom,ratiometric;
		qcom,hw-settle-time = <200>;
	};
	usb_temp_adc {
		reg = <ADC_AMUX_THM2_PU2>;
		label = "usb_temp_adc";
		qcom,pre-scaling = <1 1>;
		qcom,ratiometric;
		qcom,hw-settle-time = <200>;
	};
};
